# NUC1xx_registers register map
File version: 0.1
CPU: 
Registers are 32-bit, read-write, reset 0x0 unless marked. A register's access mark holds for its fields unless they carry their own. Offsets are from the block's base; [hi:lo] are bit positions; lines under a group give offsets from that group; {n}, {i} and the like mark numbered series; 'fields as' and 'values as' point back to an identical list.

## USB — Registers group
Base 0x40060000
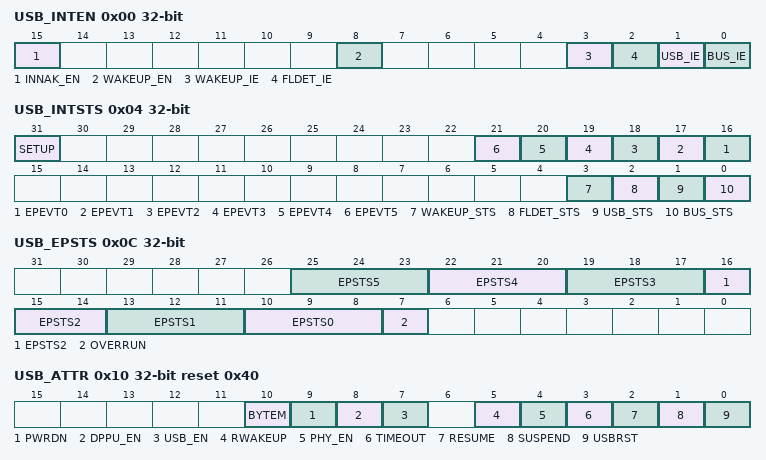
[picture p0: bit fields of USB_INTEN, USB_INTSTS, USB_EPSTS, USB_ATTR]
0x00 USB_INTEN — Interrupt Enable Flag
  [15] INNAK_EN wo — 1 = The NAK status is updated into the endpoint status register, USB_EPSTS, when it is set to 1 and there is NAK response in IN token. It also enable the interrupt event when the device responds NAK after receiving IN token. 0 = The NAK status doesn't be updated into the endpoint status register when it was set to 0. It also disable the interrupt event when device responds NAK after receiving IN token
  [8] WAKEUP_EN — 1/0: Enable/Disable USB wakeup function
  [3] WAKEUP_IE — 1/0: Enable/disable Wakeup Interrupt.
  [2] FLDET_IE — 1/0: Enable/disable Floating detect Interrupt
  [1] USB_IE — 1/0: Enable/disable USB event interrupt.
  [0] BUS_IE — 1/0: Enable/disable BUS event interrupt.
0x04 USB_INTSTS — Interrupt Event Flag
  [31] SETUP write-1-clears — 1 = Setup event occurred, cleared by write 1 to USB_INTSTS[31] 0 = No Setup event
  [n+16] EPEVT{n} write-1-clears (n=0..5) — 1 = USB event occurred on Endpoint {n}, check USB_EPSTS[{3n+10}:{3n+8}] to know which kind of USB event was occurred, cleared by write 1 to USB_INTSTS[{n+16}] or USB_INTSTS[1] 0 = No event occurred in endpoint {n}
  [3] WAKEUP_STS write-1-clears — 1 = Wakeup event occurred, cleared by write 1 to USB_INTSTS[3] 0 = No Wakeup event is occurred
  [2] FLDET_STS write-1-clears — 1 = There is attached/detached event in the USB bus and it is cleared by write 1 to USB_INTSTS[2]. 0 = There is not attached/detached event in the USB
  [1] USB_STS write-1-clears — The USB event includes the Setup Token, IN Token, OUT ACK, ISO IN, or ISO OUT events in the bus. 1 = USB event occurred, check EPSTS0~5[2:0] to know which kind of USB event was occurred, cleared by write 1 to USB_INTSTS[1] or EPSTS0~5 and SETUP (USB_INTSTS[31]) 0 = No any USB event is occurred
  [0] BUS_STS write-1-clears — The BUS event means that there is one of the suspense or the resume function in the bus. 1 = Bus event occurred; check USB_ATTR[3:0] to know which kind of bus event was occurred, cleared by write 1 to USB_INTSTS[0]. 0 = No any BUS event is occurred
0x08 USB_FADDR — Function Address
  [6:0] FADDR — Function Address of this USB device.
0x0C USB_EPSTS ro (reset mask 0xFFFFFF0F) — System state
  [3n+10:3n+8] EPSTS{n} (n=0..5) — These bits are used to indicate the current status of this endpoint 000 = In ACK 001 = In NAK 010 = Out Packet Data0 ACK 110 = Out Packet Data1 ACK 011 = Setup ACK 111 = Isochronous transfer end
  [7] OVERRUN — It indicates that the received data is over the maximum payload number or not. 1 = It indicates that the Out Data more than the Max Payload in MXPLD register or the Setup Data more than 8 Bytes 0 = No overrun
0x10 USB_ATTR reset 0x40 — Bus state & attribution
  [10] BYTEM — 1: Byte Mode. The size of the transfer from CPU to USB SRAM can be Byte only. 0: Word Mode. The size of the transfer from CPU to USB SRAM can be Word. only
  [9] PWRDN — 1: Turn-on related circuit of PHY transceiver 0: power-down related circuit of PHY transceiver
  [8] DPPU_EN — Pull-up resistor on USB_DP enable bit 1: Enable 0: Disable
  [7] USB_EN — 1: Enable USB controller. 0: Disable USB controller.
  [5] RWAKEUP — 1: Force USB bus to K state, used for remote wake-up. 0: Release the USB bus from K state.
  [4] PHY_EN — 1: Enable PHY transceiver function. 0: Disable PHY transceiver function.
  [3] TIMEOUT ro — 1: No response more than 18 bits time 0: No time out.
  [2] RESUME ro — 1: Resume from suspension 0: No bus resume.
  [1] SUSPEND ro — 1: Bus idle more than 3mS, either cable is plugged off or host is sleeping. 0: Bus no suspend.
  [0] USBRST ro — 1: Bus reset when SE0(single-ended 0) more than 2.5uS. 0: Bus no reset.
0x14 USB_FLDET ro — Device Floating Detected
  [0] FLDET — 1: When the controller is attached into the BUS, this bit will be set as 1 0: The controller didn't attached into the USB host
0x18 USB_BUFSEG — Buffer Segmentation
  [8:3] BUFSEG — It is used to indicate the offset address for the Setup token with the USB SRAM starting address. The effective starting address is USB_SRAM address + { BUFSEG[8:3], 3'b000} Where the USB_SRAM address = 0x40060100h. Note: It is used for Setup token only.
0x20 USB_BUFSEG0 — Buffer Segmentation of endpoint 0
  [8:3] BUFSEG0 — It is used to indicate the offset address for each endpoint with the USB SRAM starting address. The effective starting address of the endpoint is: USB_SRAM address + { BUFSEG0[8:3], 3'b000} Where the USB_SRAM address = 0x40060100h. Refer to section 5.4.4.7 for the endpoint SRAM structure and its description.
{0x24+0x10*i} USB_MXPLD{i} (i=0..5) — Maximal payload of endpoint {i}
  [8:0] MXPLD — It is used to define the data length which is transmitted to host (IN token) or the actual data length which is received from the host (OUT token). It also used to indicate that the endpoint is ready to be transmitted in IN token or received in OUT token. (1). When the register is written by CPU, For IN token, the value of MXPLD is used to define the data length to be transmitted and indicate the data buffer is ready. For OUT token, it means that the controller is ready to receive data from the host and the value of MXPLD is the maximal data length comes from host. (2). When the register is read by CPU, For IN token, the value of MXPLD is indicated the data length be transmitted to host. For OUT token, the value of MXPLD is indicated the actual data length receiving from host. Note that once MXPLD is written, the data packets will be transmitted/received immediately after IN/OUT token arrived.
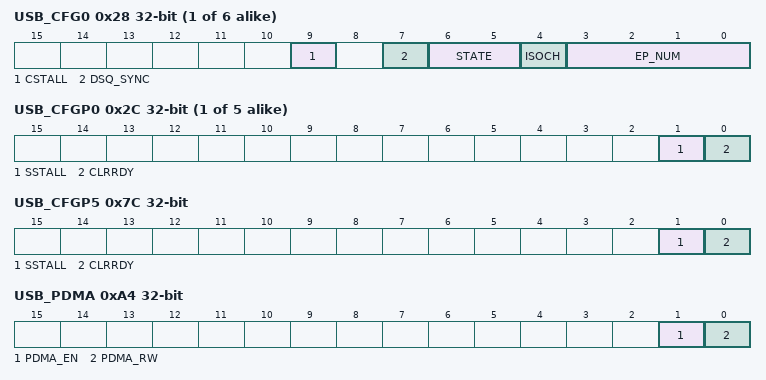
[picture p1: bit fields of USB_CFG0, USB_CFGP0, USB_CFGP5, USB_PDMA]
{0x28+0x10*i} USB_CFG{i} (i=0..5) — Configuration of endpoint {i}
  [9] CSTALL — 1 = Clear the device to response STALL handshake in setup stage 0 = Disable the device to clear the STALL handshake in setup stage
  [7] DSQ_SYNC — 1 = DATA1 PID 0 = DATA0 PID It is used to specify the DATA0 or DATA1 PID in the following IN token transaction. H/W will toggle automatically in IN token base on the bit.
  [6:5] STATE — 00 = Endpoint is disabled 01 = OUT endpoint 10 = IN endpoint 11 = Undefined
  [4] ISOCH — This bit is used to set the endpoint as Isochronous endpoint, no handshake. 1: Isochronous endpoint 0: No Isochronous endpoint
  [3:0] EP_NUM — These bits are used to define the endpoint number of the current endpoint.
{0x2C+0x10*i} USB_CFGP{i} (i=0..4) — stall control register and In/out ready clear flag of endpoint {i}
  [1] SSTALL — 1 = Set the device to respond STALL automatically 0 = Disable the device to response STALL
  [0] CLRRDY wo write-1-clears — When the MXPLD register is set by user, it means that the endpoint is ready to transmit or receive data. If the user wants to turn off this transaction before the transaction start, users can set this bit to 1 to turn it off and it is auto clear to 0. For IN token, write 1 is used to clear the IN token had ready to transmit the data to USB. For OUT token, write 1 is used to clear the OUT token had ready to receive the data from USB. This bit is write 1 only and it is always 0 when it was read back.
0x30 USB_BUFSEG1 — Buffer Segmentation of endpoint 1
  [8:3] BUFSEG1 — It is used to indicate the offset address for each endpoint with the USB SRAM starting address. The effective starting address of the endpoint is: USB_SRAM address + { BUFSEG1[8:3], 3'b000} Where the USB_SRAM address = 0x40060100h. Refer to section 5.4.4.7 for the endpoint SRAM structure and its description.
0x40 USB_BUFSEG2 — Buffer Segmentation of endpoint 2
  [8:3] BUFSEG2 — It is used to indicate the offset address for each endpoint with the USB SRAM starting address. The effective starting address of the endpoint is: USB_SRAM address + { BUFSEG2[8:3], 3'b000} Where the USB_SRAM address = 0x40060100h. Refer to section 5.4.4.7 for the endpoint SRAM structure and its description.
0x50 USB_BUFSEG3 — Buffer Segmentation of endpoint 3
  [8:3] BUFSEG3 — It is used to indicate the offset address for each endpoint with the USB SRAM starting address. The effective starting address of the endpoint is: USB_SRAM address + { BUFSEG3[8:3], 3'b000} Where the USB_SRAM address = 0x40060100h. Refer to section 5.4.4.7 for the endpoint SRAM structure and its description.
0x60 USB_BUFSEG4 — Buffer Segmentation of endpoint 4
  [8:3] BUFSEG4 — It is used to indicate the offset address for each endpoint with the USB SRAM starting address. The effective starting address of the endpoint is: USB_SRAM address + { BUFSEG4[8:3], 3'b000} Where the USB_SRAM address = 0x40060100h. Refer to section 5.4.4.7 for the endpoint SRAM structure and its description.
0x70 USB_BUFSEG5 — Buffer Segmentation of endpoint 5
  [8:3] BUFSEG5 — It is used to indicate the offset address for each endpoint with the USB SRAM starting address. The effective starting address of the endpoint is: USB_SRAM address + { BUFSEG5[8:3], 3'b000} Where the USB_SRAM address = 0x40060100h. Refer to section 5.4.4.7 for the endpoint SRAM structure and its description.
0x7C USB_CFGP5 — In ready clear flag of endpoint 5
  fields as USB_CFGP0
0x90 USB_DRVSE0 reset 0x1 (reset mask 0xFFFFFFFE) — Drive Single Ended Zero (SE0) in USB Bus
  [0] DRVSE0 — The Single Ended Zero (SE0) is when both lines (USB_DP and USB_DM) are being pulled low. 1 = Force USB PHY transceiver to drive SE0 0 = None
0xA4 USB_PDMA — New description for register
  [1] PDMA_EN — 1 = The PDMA function in USB is enabled 0 = The PDMA function in USB is disabled This bit will be automatically cleared after PDMA transfer done
  [0] PDMA_RW — 1 = The USB PDMA read data from USB buffer to memory 0 = The USB PDMA write data from memory to USB buffer
